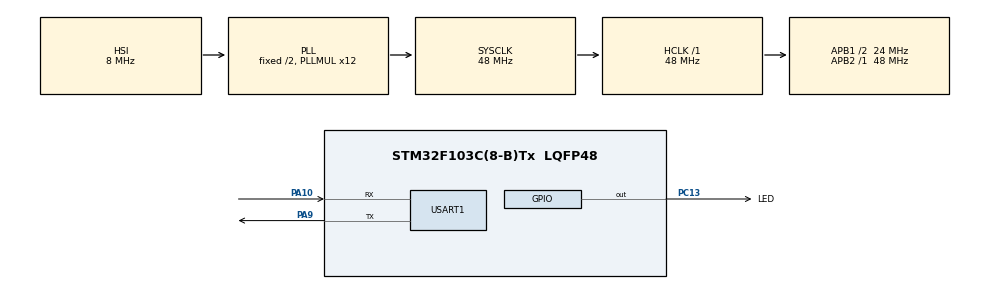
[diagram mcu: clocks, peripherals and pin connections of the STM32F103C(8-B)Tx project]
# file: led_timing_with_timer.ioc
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Dma.Request0=USART1_RX
Dma.USART1_RX.0.Direction=DMA_PERIPH_TO_MEMORY
Dma.USART1_RX.0.Instance=DMA1_Channel5
Dma.USART1_RX.0.MemDataAlignment=DMA_MDATAALIGN_BYTE
Dma.USART1_RX.0.MemInc=DMA_MINC_ENABLE
Dma.USART1_RX.0.Mode=DMA_NORMAL
Dma.USART1_RX.0.PeriphDataAlignment=DMA_PDATAALIGN_BYTE
Dma.USART1_RX.0.PeriphInc=DMA_PINC_DISABLE
Dma.USART1_RX.0.Priority=DMA_PRIORITY_LOW
Mcu.Family=STM32F1
Mcu.Name=STM32F103C(8-B)Tx
Mcu.Package=LQFP48
NVIC.DMA1_Channel5_IRQn=true\:0\:0\:false\:false\:true\:false\:true
NVIC.PriorityGroup=NVIC_PRIORITYGROUP_4
NVIC.TIM3_IRQn=true\:0\:0\:false\:false\:true\:true\:true
NVIC.USART1_IRQn=true\:0\:0\:false\:false\:true\:true\:true
PA10.Mode=Asynchronous
PA10.Signal=USART1_RX
PA13.Mode=Serial_Wire
PA13.Signal=SYS_JTMS-SWDIO
PA14.Mode=Serial_Wire
PA14.Signal=SYS_JTCK-SWCLK
PA9.Mode=Asynchronous
PA9.Signal=USART1_TX
PC13-TAMPER-RTC.GPIO_Label=LED
PC13-TAMPER-RTC.Signal=GPIO_Output
PD0-OSC_IN.Mode=HSE-External-Oscillator
PD0-OSC_IN.Signal=RCC_OSC_IN
PD1-OSC_OUT.Mode=HSE-External-Oscillator
PD1-OSC_OUT.Signal=RCC_OSC_OUT
ProjectManager.HeapSize=0x200
ProjectManager.StackSize=0x400
ProjectManager.TargetToolchain=STM32CubeIDE
RCC.AHBFreq_Value=48000000
RCC.APB1CLKDivider=RCC_HCLK_DIV2
RCC.APB1Freq_Value=24000000
RCC.APB1TimFreq_Value=48000000
RCC.APB2Freq_Value=48000000
RCC.APB2TimFreq_Value=48000000
RCC.HCLKFreq_Value=48000000
RCC.PLLMUL=RCC_PLL_MUL12
RCC.SYSCLKFreq_VALUE=48000000
RCC.SYSCLKSource=RCC_SYSCLKSOURCE_PLLCLK
RCC.USBFreq_Value=48000000
TIM3.AutoReloadPreload=TIM_AUTORELOAD_PRELOAD_ENABLE
TIM3.Period=1
TIM3.Prescaler=24112
USART1.VirtualMode=VM_ASYNC
VP_TIM3_VS_ClockSourceINT.Mode=Internal
board=custom

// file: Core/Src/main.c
/* USER CODE BEGIN Header */

/* USER CODE END Header */

#include "main.h"

void SystemClock_Config(void);

int main(void) {

	/* MCU Configuration--------------------------------------------------------*/

	/* Reset of all peripherals, Initializes the Flash interface and the Systick. */
	HAL_Init();

	/* Configure the system clock */
	SystemClock_Config();

	/* Initialize all configured peripherals */
	MX_GPIO_Init();
	MX_DMA_Init();
	MX_TIM3_Init();
	MX_USART1_UART_Init();
	/* USER CODE BEGIN 2 */
	HAL_UARTEx_ReceiveToIdle_DMA(&huart1, run.rx_data, 50);
	HAL_TIM_Base_Start_IT(&htim3);

	run.led_off_time = 250;
	run.led_on_time = 250;
	/* USER CODE END 2 */

	/* Infinite loop */
	/* USER CODE BEGIN WHILE */
	while (1) {
		if (run.new_data) {
			HAL_UART_Transmit(&huart1, run.rx_data, run.pck_lenght, 100);		// receive message to send echo
			Command_Parser();

			if (run.cmd.invalid_flg) {
				Send_Message(" Invalid Command ");
				run.cmd.invalid_flg = 0;
			} else {
				Send_Message(" OK.. ");

				if (run.cmd.new_cmd_flg) {
					switch (run.cmd.command) {
					case LED_ON_TIME:
						run.led_on_time = run.cmd.cmd_val;
						break;
					case LED_OFF_TIME:
						run.led_off_time = run.cmd.cmd_val;
						break;
					case BAUDRATE:
						Send_Message(" Change UART Baudrate...");
						huart1.Init.BaudRate = run.cmd.cmd_val;
						HAL_UART_Init(&huart1);
						break;
					}
				}
			}

			huart1.Instance->CR1 |= (1 << 4);								// receiver to idle interrupt flag set
			run.new_data = 0;												// clear new data flag
			memset(&run.rx_data, 0x00, 50);									// usart rx data clear
		}
	}
	/* USER CODE END WHILE */

}

void SystemClock_Config(void) {
	RCC_OscInitTypeDef RCC_OscInitStruct = { 0 };
	RCC_ClkInitTypeDef RCC_ClkInitStruct = { 0 };

	/** Initializes the CPU, AHB and APB busses clocks
	 */
	RCC_OscInitStruct.OscillatorType = RCC_OSCILLATORTYPE_HSI;
	RCC_OscInitStruct.HSIState = RCC_HSI_ON;
	RCC_OscInitStruct.HSICalibrationValue = RCC_HSICALIBRATION_DEFAULT;
	RCC_OscInitStruct.PLL.PLLState = RCC_PLL_ON;
	RCC_OscInitStruct.PLL.PLLSource = RCC_PLLSOURCE_HSI_DIV2;
	RCC_OscInitStruct.PLL.PLLMUL = RCC_PLL_MUL12;
	if (HAL_RCC_OscConfig(&RCC_OscInitStruct) != HAL_OK) {
		Error_Handler();
	}
	/** Initializes the CPU, AHB and APB busses clocks
	 */
	RCC_ClkInitStruct.ClockType = RCC_CLOCKTYPE_HCLK | RCC_CLOCKTYPE_SYSCLK
			| RCC_CLOCKTYPE_PCLK1 | RCC_CLOCKTYPE_PCLK2;
	RCC_ClkInitStruct.SYSCLKSource = RCC_SYSCLKSOURCE_PLLCLK;
	RCC_ClkInitStruct.AHBCLKDivider = RCC_SYSCLK_DIV1;
	RCC_ClkInitStruct.APB1CLKDivider = RCC_HCLK_DIV2;
	RCC_ClkInitStruct.APB2CLKDivider = RCC_HCLK_DIV1;

	if (HAL_RCC_ClockConfig(&RCC_ClkInitStruct, FLASH_LATENCY_1) != HAL_OK) {
		Error_Handler();
	}
}

void Error_Handler(void) {
}

/************************ (C) COPYRIGHT STMicroelectronics *****END OF FILE****/
